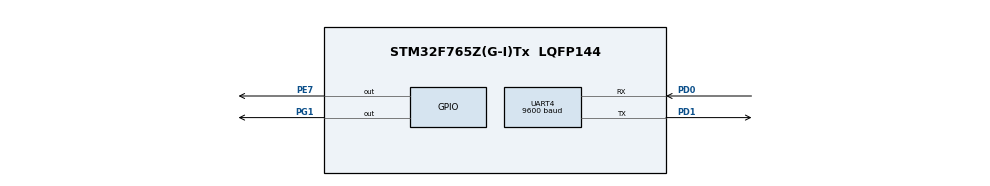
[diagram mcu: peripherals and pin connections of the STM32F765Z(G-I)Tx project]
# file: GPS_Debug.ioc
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Mcu.Family=STM32F7
Dma.UART4_RX.0.MemInc=DMA_MINC_ENABLE
Dma.UART4_TX.1.PeriphDataAlignment=DMA_PDATAALIGN_BYTE
PG1.Signal=GPIO_Output
NVIC.DMA1_Stream2_IRQn=true\:0\:0\:false\:false\:true\:false\:true
Dma.UART4_RX.0.Mode=DMA_NORMAL
PD1.Signal=UART4_TX
NVIC.DMA1_Stream4_IRQn=true\:0\:0\:false\:false\:true\:false\:true
PB15.Signal=UART4_CTS
ProjectManager.StackSize=0x400
Dma.UART4_RX.0.Direction=DMA_PERIPH_TO_MEMORY
ProjectManager.TargetToolchain=STM32CubeIDE
Dma.UART4_TX.1.Instance=DMA1_Stream4
UART4.BaudRate=9600
PD0.Signal=UART4_RX
RCC.USBFreq_Value=96000000
Dma.UART4_RX.0.PeriphInc=DMA_PINC_DISABLE
RCC.LSE_VALUE=32768
Dma.UART4_TX.1.FIFOMode=DMA_FIFOMODE_DISABLE
PB14.Signal=UART4_RTS
RCC.HSE_VALUE=25000000
board=custom
RCC.VCOOutputFreq_Value=192000000
Dma.UART4_TX.1.Mode=DMA_NORMAL
Dma.UART4_RX.0.MemDataAlignment=DMA_MDATAALIGN_BYTE
Dma.UART4_RX.0.FIFOMode=DMA_FIFOMODE_DISABLE
PD1.Mode=Asynchronous
Dma.UART4_RX.0.Priority=DMA_PRIORITY_LOW
Dma.UART4_RX.0.PeriphDataAlignment=DMA_PDATAALIGN_BYTE
Mcu.Name=STM32F765Z(G-I)Tx
PD0.Mode=Asynchronous
Mcu.Package=LQFP144
UART4.OverrunDisableParam=UART_ADVFEATURE_OVERRUN_DISABLE
UART4.DMADisableonRxErrorParam=UART_ADVFEATURE_DMA_DISABLEONRXERROR
Dma.UART4_TX.1.MemInc=DMA_MINC_ENABLE
Dma.UART4_TX.1.PeriphInc=DMA_PINC_DISABLE
ProjectManager.HeapSize=0x200
Dma.UART4_TX.1.Priority=DMA_PRIORITY_LOW
RCC.HSI_VALUE=16000000
UART4.MSBFirstParam=UART_ADVFEATURE_MSBFIRST_DISABLE
NVIC.PriorityGroup=NVIC_PRIORITYGROUP_4
Dma.UART4_RX.0.Instance=DMA1_Stream2
Dma.UART4_TX.1.MemDataAlignment=DMA_MDATAALIGN_BYTE
Dma.Request1=UART4_TX
PE7.Signal=GPIO_Output
Dma.Request0=UART4_RX
UART4.OverSampling=UART_OVERSAMPLING_8
NVIC.UART4_IRQn=true\:0\:0\:false\:false\:true\:true\:true
Dma.UART4_TX.1.Direction=DMA_MEMORY_TO_PERIPH

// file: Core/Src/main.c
/* USER CODE BEGIN Header */
/**
  ******************************************************************************
  * @file           : main.c
  * @brief          : Main program body
  ******************************************************************************
  * @attention
  *
  * <h2><center>&copy; Copyright (c) 2021 STMicroelectronics.
  * All rights reserved.</center></h2>
  *
  * This software component is licensed by ST under BSD 3-Clause license,
  * the "License"; You may not use this file except in compliance with the
  * License. You may obtain a copy of the License at:
  *                        opensource.org/licenses/BSD-3-Clause
  *
  ******************************************************************************
  */
/* USER CODE END Header */
#include "main.h"

/* USER CODE BEGIN Includes */

#include "gps.h"

/* USER CODE END Includes */

UART_HandleTypeDef huart4;
DMA_HandleTypeDef hdma_uart4_rx;
DMA_HandleTypeDef hdma_uart4_tx;

void SystemClock_Config(void);
static void MX_GPIO_Init(void);
static void MX_DMA_Init(void);
static void MX_UART4_Init(void);

int main(void)
{

  /* MCU Configuration--------------------------------------------------------*/

  /* Reset of all peripherals, Initializes the Flash interface and the Systick. */
  HAL_Init();

  /* Configure the system clock */
  SystemClock_Config();

  /* Initialize all configured peripherals */
  MX_GPIO_Init();
  MX_DMA_Init();
  MX_UART4_Init();
  /* USER CODE BEGIN 2 */

  init();

  GPSData gpsdata;

  /* USER CODE END 2 */

  /* Infinite loop */
  /* USER CODE BEGIN WHILE */
  while (1)
  {
	  if (isNewDataAvailable()) {
		  HAL_GPIO_TogglePin(GPIOG, GPIO_PIN_1);
		  gpsdata = getData();

		  if (gpsdata.ggaDataIsNew && gpsdata.vtgDataIsNew) {
			  HAL_GPIO_TogglePin(GPIOE, GPIO_PIN_7);
		  }
	  }

    /* USER CODE END WHILE */

  }
}

void SystemClock_Config(void)
{
  RCC_OscInitTypeDef RCC_OscInitStruct = {0};
  RCC_ClkInitTypeDef RCC_ClkInitStruct = {0};
  RCC_PeriphCLKInitTypeDef PeriphClkInitStruct = {0};

  /** Configure the main internal regulator output voltage
  */
  __HAL_RCC_PWR_CLK_ENABLE();
  __HAL_PWR_VOLTAGESCALING_CONFIG(PWR_REGULATOR_VOLTAGE_SCALE3);
  /** Initializes the RCC Oscillators according to the specified parameters
  * in the RCC_OscInitTypeDef structure.
  */
  RCC_OscInitStruct.OscillatorType = RCC_OSCILLATORTYPE_HSI;
  RCC_OscInitStruct.HSIState = RCC_HSI_ON;
  RCC_OscInitStruct.HSICalibrationValue = RCC_HSICALIBRATION_DEFAULT;
  RCC_OscInitStruct.PLL.PLLState = RCC_PLL_NONE;
  if (HAL_RCC_OscConfig(&RCC_OscInitStruct) != HAL_OK)
  {
    Error_Handler();
  }
  /** Initializes the CPU, AHB and APB buses clocks
  */
  RCC_ClkInitStruct.ClockType = RCC_CLOCKTYPE_HCLK|RCC_CLOCKTYPE_SYSCLK
                              |RCC_CLOCKTYPE_PCLK1|RCC_CLOCKTYPE_PCLK2;
  RCC_ClkInitStruct.SYSCLKSource = RCC_SYSCLKSOURCE_HSI;
  RCC_ClkInitStruct.AHBCLKDivider = RCC_SYSCLK_DIV1;
  RCC_ClkInitStruct.APB1CLKDivider = RCC_HCLK_DIV1;
  RCC_ClkInitStruct.APB2CLKDivider = RCC_HCLK_DIV1;

  if (HAL_RCC_ClockConfig(&RCC_ClkInitStruct, FLASH_LATENCY_0) != HAL_OK)
  {
    Error_Handler();
  }
  PeriphClkInitStruct.PeriphClockSelection = RCC_PERIPHCLK_UART4;
  PeriphClkInitStruct.Uart4ClockSelection = RCC_UART4CLKSOURCE_PCLK1;
  if (HAL_RCCEx_PeriphCLKConfig(&PeriphClkInitStruct) != HAL_OK)
  {
    Error_Handler();
  }
}

static void MX_UART4_Init(void)
{

  huart4.Instance = UART4;
  huart4.Init.BaudRate = 9600;
  huart4.Init.WordLength = UART_WORDLENGTH_8B;
  huart4.Init.StopBits = UART_STOPBITS_1;
  huart4.Init.Parity = UART_PARITY_NONE;
  huart4.Init.Mode = UART_MODE_TX_RX;
  huart4.Init.HwFlowCtl = UART_HWCONTROL_NONE;
  huart4.Init.OverSampling = UART_OVERSAMPLING_8;
  huart4.Init.OneBitSampling = UART_ONE_BIT_SAMPLE_DISABLE;
  huart4.AdvancedInit.AdvFeatureInit = UART_ADVFEATURE_RXOVERRUNDISABLE_INIT|UART_ADVFEATURE_DMADISABLEONERROR_INIT;
  huart4.AdvancedInit.OverrunDisable = UART_ADVFEATURE_OVERRUN_DISABLE;
  huart4.AdvancedInit.DMADisableonRxError = UART_ADVFEATURE_DMA_DISABLEONRXERROR;
  if (HAL_UART_Init(&huart4) != HAL_OK)
  {
    Error_Handler();
  }

}

static void MX_DMA_Init(void)
{

  /* DMA controller clock enable */
  __HAL_RCC_DMA1_CLK_ENABLE();

  /* DMA interrupt init */
  /* DMA1_Stream2_IRQn interrupt configuration */
  HAL_NVIC_SetPriority(DMA1_Stream2_IRQn, 0, 0);
  HAL_NVIC_EnableIRQ(DMA1_Stream2_IRQn);
  /* DMA1_Stream4_IRQn interrupt configuration */
  HAL_NVIC_SetPriority(DMA1_Stream4_IRQn, 0, 0);
  HAL_NVIC_EnableIRQ(DMA1_Stream4_IRQn);

}

static void MX_GPIO_Init(void)
{
  GPIO_InitTypeDef GPIO_InitStruct = {0};

  /* GPIO Ports Clock Enable */
  __HAL_RCC_GPIOG_CLK_ENABLE();
  __HAL_RCC_GPIOE_CLK_ENABLE();
  __HAL_RCC_GPIOB_CLK_ENABLE();
  __HAL_RCC_GPIOD_CLK_ENABLE();

  /*Configure GPIO pin Output Level */
  HAL_GPIO_WritePin(GPIOG, GPIO_PIN_1, GPIO_PIN_RESET);

  /*Configure GPIO pin Output Level */
  HAL_GPIO_WritePin(GPIOE, GPIO_PIN_7, GPIO_PIN_RESET);

  /*Configure GPIO pin : PG1 */
  GPIO_InitStruct.Pin = GPIO_PIN_1;
  GPIO_InitStruct.Mode = GPIO_MODE_OUTPUT_PP;
  GPIO_InitStruct.Pull = GPIO_NOPULL;
  GPIO_InitStruct.Speed = GPIO_SPEED_FREQ_LOW;
  HAL_GPIO_Init(GPIOG, &GPIO_InitStruct);

  /*Configure GPIO pin : PE7 */
  GPIO_InitStruct.Pin = GPIO_PIN_7;
  GPIO_InitStruct.Mode = GPIO_MODE_OUTPUT_PP;
  GPIO_InitStruct.Pull = GPIO_NOPULL;
  GPIO_InitStruct.Speed = GPIO_SPEED_FREQ_LOW;
  HAL_GPIO_Init(GPIOE, &GPIO_InitStruct);

}

void Error_Handler(void)
{
  __disable_irq();
  while (1)
  {
  }
}

/************************ (C) COPYRIGHT STMicroelectronics *****END OF FILE****/
